# SF32LB56x register map
File version: 1.0
CPU: CM33 r0p1, little endian, MPU, FPU, 3 interrupt priority bits
Registers are 32-bit, read-write, reset 0x0 unless marked. A register's access mark holds for its fields unless they carry their own. Offsets are from the block's base; lines under a group give offsets from that group; [hi:lo] are bit positions; {n}, {i} and the like mark numbered series; 'fields as' and 'values as' point back to an identical list; <NAME> marks a mode.

## Memory map
0x40000000 HPSYS_RCC size 0x1000
0x40001000 DMAC1 size 0x1000
0x40003000 HPSYS_PINMUX size 0x1000
0x40004000 USART1 size 0x1000
0x40005000 USART2 size 0x1000
0x40006000 EZIP1 size 0x1000
0x40007000 EPIC size 0x1000
0x40008000 LCDC1 size 0x1000
0x40009000 I2S1 size 0x1000
0x4000B000 HPSYS_CFG size 0x1000
0x4000C000 EFUSEC size 0x1000
0x4000D000 AES size 0x1000
0x4000F000 TRNG size 0x1000
0x40010000 GPTIM1 size 0x1000
0x40011000 GPTIM2 size 0x1000
0x40012000 BTIM1 size 0x1000
0x40013000 BTIM2 size 0x1000
0x40014000 WDT1 size 0x1000
0x40015000 SPI1 size 0x1000
0x40016000 SPI2 size 0x1000
0x40017000 EXTDMA size 0x1000
0x4001A000 PDM1 size 0x1000
0x4001B000 PDM2 size 0x1000
0x4001C000 I2C1 size 0x1000
0x4001D000 I2C2 size 0x1000
0x40020000 PTC1 size 0x1000
0x40022000 I2C3 size 0x1000
0x40023000 ATIM1 size 0x1000
0x40025000 AUDPRC size 0x1000
0x40026000 AUDCODEC_HP size 0x1000
0x40028000 FACC1 size 0x1000
0x40029000 USART3 size 0x1000
0x4002D000 SCI size 0x1000
0x4002F000 I2C4 size 0x1000
0x40040000 HPSYS_AON size 0x1000
0x40041000 LPTIM1 size 0x1000
0x40080000 HPSYS_GPIO size 0x1000
0x40081000 MPI1 size 0x1000
0x40082000 MPI2 size 0x1000
0x40083000 MPI3 size 0x1000
0x40084000 MPI4 size 0x1000
0x40085000 SDMMC size 0x1000
0x40086000 SD size 0x1000
0x40088000 CRC1 size 0x1000
0x50000000 LPSYS_RCC size 0x1000
0x50001000 DMAC2 size 0x1000
0x50003000 LPSYS_PINMUX size 0x1000
0x50005000 USART4 size 0x1000
0x50006000 USART5 size 0x1000
0x50007000 USART6 size 0x1000
0x50009000 SPI3 size 0x1000
0x5000A000 SPI4 size 0x1000
0x5000B000 WDT2 size 0x1000
0x5000C000 I2C5 size 0x1000
0x5000D000 I2C6 size 0x1000
0x5000E000 I2C7 size 0x1000
0x5000F000 LPSYS_CFG size 0x1000
0x50010000 GPTIM3 size 0x1000
0x50011000 GPTIM4 size 0x1000
0x50012000 GPTIM5 size 0x1000
0x50013000 BTIM3 size 0x1000
0x50014000 BTIM4 size 0x1000
0x50016000 GPADC size 0x1000
0x50018000 AUDCODEC_LP size 0x1000
0x5001A000 TSEN size 0x1000
0x5001B000 PTC2 size 0x1000
0x50040000 LPSYS_AON size 0x1000
0x50041000 LPTIM2 size 0x1000
0x50042000 LPTIM3 size 0x1000
0x5004A000 PMUC size 0x1000
0x5004B000 RTC size 0x1000
0x5004C000 IWDT size 0x1000
0x50080000 LPSYS_GPIO size 0x1000
0x50081000 MPI5 size 0x1000
0x50085000 CRC2 size 0x1000

## HPSYS_PINMUX
Base 0x40003000
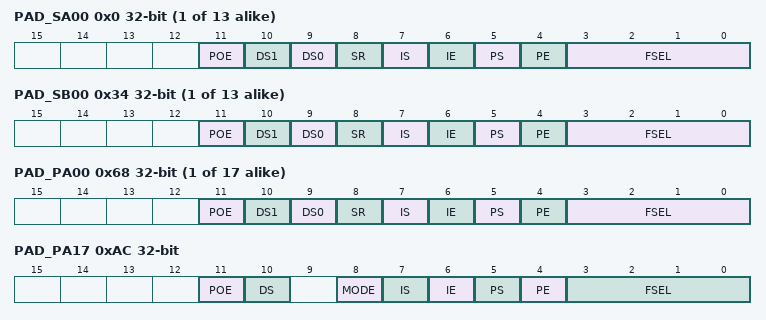
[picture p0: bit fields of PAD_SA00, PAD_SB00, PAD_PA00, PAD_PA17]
{0x0+4i} PAD_SA{i:02} (i=0..12)
  [11] POE — Reserved. Always set to logic LOW
  [10] DS1 — Drive Select 1. Used to select output drive strength
  [9] DS0 — Drive Select 0. Used to select output drive strength
  [8] SR — Slew Rate. Logic HIGH selects slow slew rate, logic LOW selects fast slew rate
  [7] IS — Input Select. Logic LOW selects CMOS input, logic HIGH selects Schmitt input
  [6] IE — Input Enable. Logic HIGH enables the input buffer
  [5] PS — Pull Select. Logic HIGH selects pull-up, logic LOW select pull-down
  [4] PE — Pull Enable. Logic HIGH enables week pull device
  [3:0] FSEL — Function Select
{0x34+4i} PAD_SB{i:02} (i=0..12)
  fields as PAD_SA00
{0x68+4i} PAD_PA{i:02} (i=0..16)
  fields as PAD_SA00
0xAC PAD_PA17
  [11] POE — Reserved. Always set to logic LOW
  [10] DS — Drive Select. Logic LOW selects 4mA drive,logic HIGH selects 20mA drive
  [8] MODE — Mode Select. Logic LOW enables GPIO mode,logic HIGH enables I2C mode
  [7] IS — Input Select. Logic LOW selects CMOS input, logic HIGH selects Schmitt input
  [6] IE — Input Enable. Logic HIGH enables the input buffer
  [5] PS — Pull Select. Logic HIGH selects pull-up, logic LOW select pull-down
  [4] PE — Pull Enable. Logic HIGH enables week pull device
  [3:0] FSEL — Function Select
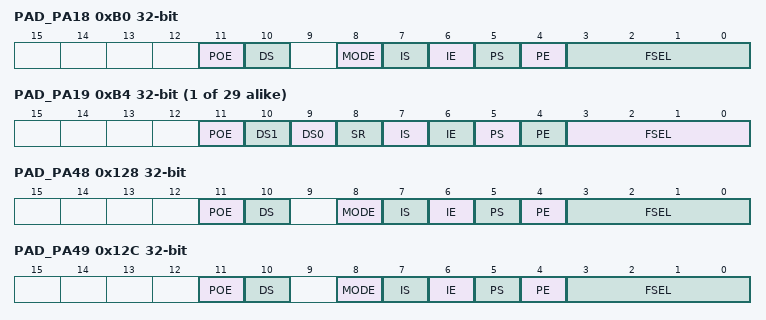
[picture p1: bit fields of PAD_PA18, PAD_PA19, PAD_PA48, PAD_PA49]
0xB0 PAD_PA18
  fields as PAD_PA17
{0x68+4i} PAD_PA{i} (i=19..47)
  fields as PAD_SA00
0x128 PAD_PA48
  fields as PAD_PA17
0x12C PAD_PA49
  fields as PAD_PA17
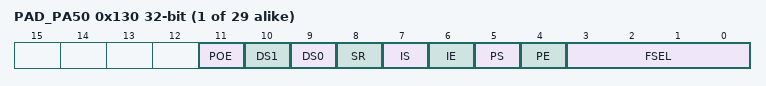
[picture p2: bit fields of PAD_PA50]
{0x68+4i} PAD_PA{i} (i=50..78)
  fields as PAD_SA00
